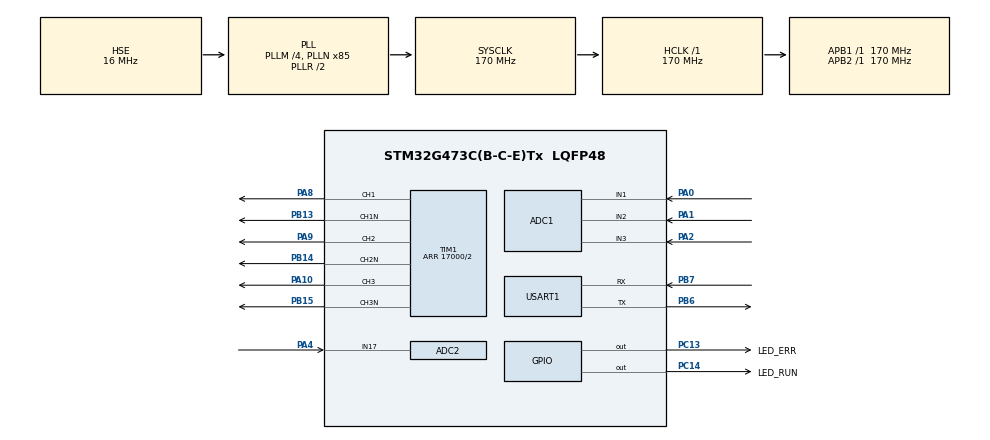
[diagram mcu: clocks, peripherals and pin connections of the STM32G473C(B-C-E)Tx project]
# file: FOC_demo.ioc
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ADC1.Channel-0\#ChannelRegularConversion=ADC_CHANNEL_1
ADC1.ContinuousConvMode=ENABLE
ADC1.EnableInjectedConversion=ENABLE
ADC1.ExternalTrigInjecConv=ADC_EXTERNALTRIGINJEC_T1_TRGO
ADC1.InjNumberOfConversion=3
ADC1.InjectedChannel-1\#ChannelInjectedConversion=ADC_CHANNEL_1
ADC1.InjectedChannel-2\#ChannelInjectedConversion=ADC_CHANNEL_2
ADC1.InjectedChannel-3\#ChannelInjectedConversion=ADC_CHANNEL_3
ADC1.InjectedOffsetNumber-1\#ChannelInjectedConversion=ADC_OFFSET_NONE
ADC1.InjectedOffsetNumber-2\#ChannelInjectedConversion=ADC_OFFSET_NONE
ADC1.InjectedOffsetNumber-3\#ChannelInjectedConversion=ADC_OFFSET_NONE
ADC1.InjectedRank-1\#ChannelInjectedConversion=1
ADC1.InjectedRank-2\#ChannelInjectedConversion=2
ADC1.InjectedRank-3\#ChannelInjectedConversion=3
ADC1.InjectedSamplingTime-1\#ChannelInjectedConversion=ADC_SAMPLETIME_12CYCLES_5
ADC1.InjectedSamplingTime-2\#ChannelInjectedConversion=ADC_SAMPLETIME_12CYCLES_5
ADC1.InjectedSamplingTime-3\#ChannelInjectedConversion=ADC_SAMPLETIME_12CYCLES_5
ADC1.NbrOfConversionFlag=1
ADC1.OffsetNumber-0\#ChannelRegularConversion=ADC_OFFSET_NONE
ADC1.Rank-0\#ChannelRegularConversion=1
ADC1.Rank1_Channel=ADC_CHANNEL_1
ADC1.Rank2_Channel=ADC_CHANNEL_2
ADC1.Rank3_Channel=ADC_CHANNEL_3
ADC1.SamplingTime-0\#ChannelRegularConversion=ADC_SAMPLETIME_2CYCLES_5
ADC1.master=1
ADC2.ContinuousConvMode=ENABLE
ADC2.EnableInjectedConversion=ENABLE
ADC2.EnableRegularConversion=DISABLE
ADC2.ExternalTrigInjecConv=ADC_EXTERNALTRIGINJEC_T1_TRGO
ADC2.InjNumberOfConversion=1
ADC2.InjectedChannel-1\#ChannelInjectedConversion=ADC_CHANNEL_17
ADC2.InjectedOffsetNumber-1\#ChannelInjectedConversion=ADC_OFFSET_NONE
ADC2.InjectedRank-1\#ChannelInjectedConversion=1
ADC2.InjectedSamplingTime-1\#ChannelInjectedConversion=ADC_SAMPLETIME_12CYCLES_5
ADC2.Rank1_Channel=ADC_CHANNEL_17
Mcu.Family=STM32G4
Mcu.Name=STM32G473C(B-C-E)Tx
Mcu.Package=LQFP48
NVIC.ADC1_2_IRQn=true\:0\:0\:false\:false\:true\:false\:true\:true\:true
NVIC.PriorityGroup=NVIC_PRIORITYGROUP_4
NVIC.TIM4_IRQn=true\:15\:0\:false\:false\:true\:false\:false\:true\:true
NVIC.TimeBase=TIM4_IRQn
NVIC.TimeBaseIP=TIM4
PA0.Mode=IN1-Single-Ended
PA0.Signal=ADC1_IN1
PA1.Mode=IN2-Single-Ended
PA1.Signal=ADC1_IN2
PA10.Signal=S_TIM1_CH3
PA13.Mode=Serial_Wire
PA13.Signal=SYS_JTMS-SWDIO
PA14.Mode=Serial_Wire
PA14.Signal=SYS_JTCK-SWCLK
PA2.Mode=IN3-Single-Ended
PA2.Signal=ADC1_IN3
PA4.Mode=IN17-Single-Ended
PA4.Signal=ADC2_IN17
PA8.Signal=S_TIM1_CH1
PA9.Signal=S_TIM1_CH2
PB13.Mode=PWM Generation1 CH1 CH1N
PB13.Signal=TIM1_CH1N
PB14.Mode=PWM Generation2 CH2 CH2N
PB14.Signal=TIM1_CH2N
PB15.Mode=PWM Generation3 CH3 CH3N
PB15.Signal=TIM1_CH3N
PB6.Mode=Asynchronous
PB6.Signal=USART1_TX
PB7.Mode=Asynchronous
PB7.Signal=USART1_RX
PC13.GPIO_Label=LED_ERR
PC13.Signal=GPIO_Output
PC14-OSC32_IN.GPIO_Label=LED_RUN
PC14-OSC32_IN.Signal=GPIO_Output
PF0-OSC_IN.Mode=HSE-External-Oscillator
PF0-OSC_IN.Signal=RCC_OSC_IN
PF1-OSC_OUT.Mode=HSE-External-Oscillator
PF1-OSC_OUT.Signal=RCC_OSC_OUT
ProjectManager.HeapSize=0x200
ProjectManager.StackSize=0x400
ProjectManager.TargetToolchain=MDK-ARM V5.32
RCC.ADC12Freq_Value=170000000
RCC.ADC345Freq_Value=170000000
RCC.AHBFreq_Value=170000000
RCC.APB1Freq_Value=170000000
RCC.APB1TimFreq_Value=170000000
RCC.APB2Freq_Value=170000000
RCC.APB2TimFreq_Value=170000000
RCC.CortexFreq_Value=170000000
RCC.EXTERNAL_CLOCK_VALUE=12288000
RCC.HCLKFreq_Value=170000000
RCC.HSE_VALUE=16000000
RCC.HSI48_VALUE=48000000
RCC.HSI_VALUE=16000000
RCC.LSE_VALUE=32768
RCC.PLLM=RCC_PLLM_DIV4
RCC.PLLN=85
RCC.PLLSourceVirtual=RCC_PLLSOURCE_HSE
RCC.SYSCLKFreq_VALUE=170000000
RCC.SYSCLKSource=RCC_SYSCLKSOURCE_PLLCLK
RCC.USBFreq_Value=170000000
RCC.VCOOutputFreq_Value=340000000
RealThread.X-CUBE-RT-Thread_Nano.4.1.1.RTAaThreadCcRTOSJjkernel=true
RealThread.X-CUBE-RT-Thread_Nano.4.1.1.RTAaThreadCcRTOSJjlibcpu=true
RealThread.X-CUBE-RT-Thread_Nano.4.1.1.RTAaThreadCcRTOSJjshell=true
RealThread.X-CUBE-RT-Thread_Nano.4.1.1.RT_USING_FINSH=1
RealThread.X-CUBE-RT-Thread_Nano.4.1.1.RT_USING_HEAP=1
RealThread.X-CUBE-RT-Thread_Nano.4.1.1.RT_USING_MESSAGEQUEUE=1
RealThread.X-CUBE-RT-Thread_Nano.4.1.1.RT_USING_SMALL_MEM=1
RealThread.X-CUBE-RT-Thread_Nano.4.1.1.RT_USING_SMALL_MEM_AS_HEAP=1
SH.S_TIM1_CH1.0=TIM1_CH1,PWM Generation1 CH1 CH1N
SH.S_TIM1_CH2.0=TIM1_CH2,PWM Generation2 CH2 CH2N
SH.S_TIM1_CH3.0=TIM1_CH3,PWM Generation3 CH3 CH3N
TIM1.AutoReloadPreload=TIM_AUTORELOAD_PRELOAD_ENABLE
TIM1.AutomaticOutput=TIM_AUTOMATICOUTPUT_ENABLE
TIM1.Channel-PWM\ Generation1\ CH1\ CH1N=TIM_CHANNEL_1
TIM1.Channel-PWM\ Generation2\ CH2\ CH2N=TIM_CHANNEL_2
TIM1.Channel-PWM\ Generation3\ CH3\ CH3N=TIM_CHANNEL_3
TIM1.CounterMode=TIM_COUNTERMODE_CENTERALIGNED1
TIM1.DeadTime=100
TIM1.DeadTimePreload=DISABLE
TIM1.LockLevel=TIM_LOCKLEVEL_1
TIM1.OCMode_PWM-PWM\ Generation1\ CH1\ CH1N=TIM_OCMODE_PWM2
TIM1.OCMode_PWM-PWM\ Generation2\ CH2\ CH2N=TIM_OCMODE_PWM2
TIM1.OCMode_PWM-PWM\ Generation3\ CH3\ CH3N=TIM_OCMODE_PWM2
TIM1.OffStateIDLEMode=TIM_OSSI_ENABLE
TIM1.OffStateRunMode=TIM_OSSR_ENABLE
TIM1.PeriodNoDither=17000/2
TIM1.PulseNoDither_1=4500
TIM1.PulseNoDither_2=4500
TIM1.PulseNoDither_3=4500
TIM1.TIM_MasterOutputTrigger=TIM_TRGO_UPDATE
USART1.VirtualMode-Asynchronous=VM_ASYNC
VP_RealThread.X-CUBE-RT-Thread_Nano_VS_RTOSJjRTAaThread_4.1.1_4.1.1.Mode=RTOSJjRTAaThread
VP_SYS_VS_DBSignals.Mode=DisableDeadBatterySignals
VP_SYS_VS_tim4.Mode=TIM4
VP_TIM1_VS_ClockSourceINT.Mode=Internal
board=custom

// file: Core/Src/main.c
/* USER CODE BEGIN Header */
/**
  ******************************************************************************
  * @file           : main.c
  * @brief          : Main program body
  ******************************************************************************
  * @attention
  *
  * Copyright (c) 2025 STMicroelectronics.
  * All rights reserved.
  *
  * This software is licensed under terms that can be found in the LICENSE file
  * in the root directory of this software component.
  * If no LICENSE file comes with this software, it is provided AS-IS.
  *
  ******************************************************************************
  */
/* USER CODE END Header */
#include "main.h"
#include "adc.h"
#include "tim.h"
#include "usart.h"
#include "gpio.h"

/* USER CODE BEGIN Includes */
#include "common.h"
/* USER CODE END Includes */

/* USER CODE BEGIN PTD */
 int fputc(int ch, FILE *f)
 {
   HAL_UART_Transmit(&huart1, (uint8_t *)&ch, 1, 0xffff);
   return ch;
 }
/* USER CODE END PTD */

void SystemClock_Config(void);

int main(void)
{

  /* MCU Configuration--------------------------------------------------------*/

  /* Reset of all peripherals, Initializes the Flash interface and the Systick. */
  HAL_Init();

  /* Configure the system clock */
  SystemClock_Config();

  /* Initialize all configured peripherals */
  MX_GPIO_Init();
  MX_USART1_UART_Init();
  MX_TIM1_Init();
  MX_ADC1_Init();
  MX_ADC2_Init();
  /* USER CODE BEGIN 2 */
  Hardware_Init();
  /* USER CODE END 2 */

  /* Infinite loop */
  /* USER CODE BEGIN WHILE */
  while (1)
  {
			HAL_GPIO_TogglePin(LED_RUN_GPIO_Port,LED_RUN_Pin);
      rt_thread_mdelay(500);
    /* USER CODE END WHILE */

  }
}

void SystemClock_Config(void)
{
  RCC_OscInitTypeDef RCC_OscInitStruct = {0};
  RCC_ClkInitTypeDef RCC_ClkInitStruct = {0};

  /** Configure the main internal regulator output voltage
  */
  HAL_PWREx_ControlVoltageScaling(PWR_REGULATOR_VOLTAGE_SCALE1_BOOST);

  /** Initializes the RCC Oscillators according to the specified parameters
  * in the RCC_OscInitTypeDef structure.
  */
  RCC_OscInitStruct.OscillatorType = RCC_OSCILLATORTYPE_HSE;
  RCC_OscInitStruct.HSEState = RCC_HSE_ON;
  RCC_OscInitStruct.PLL.PLLState = RCC_PLL_ON;
  RCC_OscInitStruct.PLL.PLLSource = RCC_PLLSOURCE_HSE;
  RCC_OscInitStruct.PLL.PLLM = RCC_PLLM_DIV4;
  RCC_OscInitStruct.PLL.PLLN = 85;
  RCC_OscInitStruct.PLL.PLLP = RCC_PLLP_DIV2;
  RCC_OscInitStruct.PLL.PLLQ = RCC_PLLQ_DIV2;
  RCC_OscInitStruct.PLL.PLLR = RCC_PLLR_DIV2;
  if (HAL_RCC_OscConfig(&RCC_OscInitStruct) != HAL_OK)
  {
    Error_Handler();
  }

  /** Initializes the CPU, AHB and APB buses clocks
  */
  RCC_ClkInitStruct.ClockType = RCC_CLOCKTYPE_HCLK|RCC_CLOCKTYPE_SYSCLK
                              |RCC_CLOCKTYPE_PCLK1|RCC_CLOCKTYPE_PCLK2;
  RCC_ClkInitStruct.SYSCLKSource = RCC_SYSCLKSOURCE_PLLCLK;
  RCC_ClkInitStruct.AHBCLKDivider = RCC_SYSCLK_DIV1;
  RCC_ClkInitStruct.APB1CLKDivider = RCC_HCLK_DIV1;
  RCC_ClkInitStruct.APB2CLKDivider = RCC_HCLK_DIV1;

  if (HAL_RCC_ClockConfig(&RCC_ClkInitStruct, FLASH_LATENCY_4) != HAL_OK)
  {
    Error_Handler();
  }
}

void HAL_TIM_PeriodElapsedCallback(TIM_HandleTypeDef *htim)
{
  if (htim->Instance == TIM4) {
    HAL_IncTick();
  }
}

void Error_Handler(void)
{
  __disable_irq();
  while (1)
  {
  }
}
